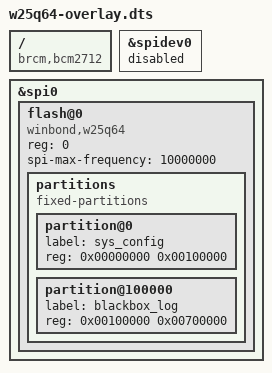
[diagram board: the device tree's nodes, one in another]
/dts-v1/;
/plugin/;

/ {
    compatible = "brcm,bcm2712";

    /* 停用預設 spidev0，釋放 CS0 */
    fragment@0 {
        target = <&spidev0>;
        __overlay__ {
            status = "disabled";
        };
    };

    /* 掛載 jedec,spi-nor 驅動並切割 MTD 分割區 */
    fragment@1 {
        target = <&spi0>;
        __overlay__ {
            status = "okay";
            #address-cells = <1>;
            #size-cells = <0>;

            flash@0 {
                compatible = "winbond,w25q64", "jedec,spi-nor";
                reg = <0>;
                spi-max-frequency = <10000000>;
                status = "okay";

                partitions {
                    compatible = "fixed-partitions";
                    #address-cells = <1>;
                    #size-cells = <1>;

                    partition@0 {
                        label = "sys_config";
                        reg = <0x00000000 0x00100000>;
                    };

                    partition@100000 {
                        label = "blackbox_log";
                        reg = <0x00100000 0x00700000>;
                    };
                };
            };
        };
    };
};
